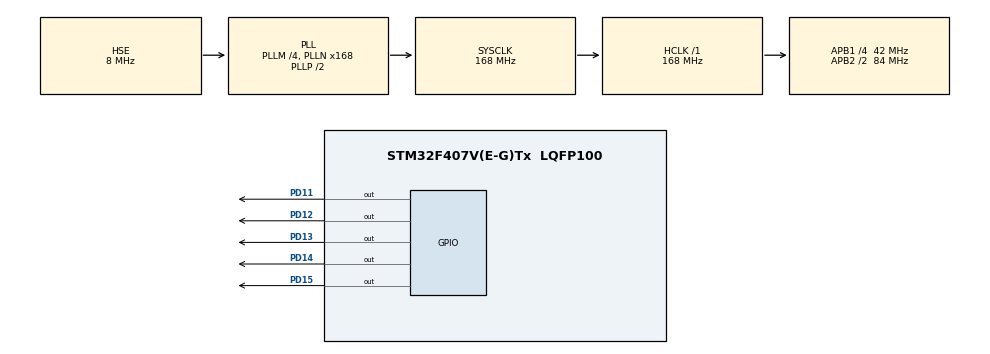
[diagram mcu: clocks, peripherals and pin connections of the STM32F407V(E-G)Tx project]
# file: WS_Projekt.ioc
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Dma.Request0=TIM1_CH4/TRIG/COM
Dma.Request1=TIM1_UP
Dma.Request2=TIM2_UP/CH3
Dma.TIM1_CH4/TRIG/COM.0.Direction=DMA_PERIPH_TO_MEMORY
Dma.TIM1_CH4/TRIG/COM.0.FIFOMode=DMA_FIFOMODE_DISABLE
Dma.TIM1_CH4/TRIG/COM.0.Instance=DMA2_Stream4
Dma.TIM1_CH4/TRIG/COM.0.MemDataAlignment=DMA_MDATAALIGN_HALFWORD
Dma.TIM1_CH4/TRIG/COM.0.MemInc=DMA_MINC_ENABLE
Dma.TIM1_CH4/TRIG/COM.0.Mode=DMA_NORMAL
Dma.TIM1_CH4/TRIG/COM.0.PeriphDataAlignment=DMA_PDATAALIGN_HALFWORD
Dma.TIM1_CH4/TRIG/COM.0.PeriphInc=DMA_PINC_DISABLE
Dma.TIM1_CH4/TRIG/COM.0.Priority=DMA_PRIORITY_LOW
Dma.TIM1_UP.1.Direction=DMA_PERIPH_TO_MEMORY
Dma.TIM1_UP.1.FIFOMode=DMA_FIFOMODE_DISABLE
Dma.TIM1_UP.1.Instance=DMA2_Stream5
Dma.TIM1_UP.1.MemDataAlignment=DMA_MDATAALIGN_BYTE
Dma.TIM1_UP.1.MemInc=DMA_MINC_ENABLE
Dma.TIM1_UP.1.Mode=DMA_NORMAL
Dma.TIM1_UP.1.PeriphDataAlignment=DMA_PDATAALIGN_BYTE
Dma.TIM1_UP.1.PeriphInc=DMA_PINC_DISABLE
Dma.TIM1_UP.1.Priority=DMA_PRIORITY_LOW
Dma.TIM2_UP/CH3.2.Direction=DMA_PERIPH_TO_MEMORY
Dma.TIM2_UP/CH3.2.FIFOMode=DMA_FIFOMODE_DISABLE
Dma.TIM2_UP/CH3.2.Instance=DMA1_Stream1
Dma.TIM2_UP/CH3.2.MemDataAlignment=DMA_MDATAALIGN_WORD
Dma.TIM2_UP/CH3.2.MemInc=DMA_MINC_ENABLE
Dma.TIM2_UP/CH3.2.Mode=DMA_NORMAL
Dma.TIM2_UP/CH3.2.PeriphDataAlignment=DMA_PDATAALIGN_WORD
Dma.TIM2_UP/CH3.2.PeriphInc=DMA_PINC_DISABLE
Dma.TIM2_UP/CH3.2.Priority=DMA_PRIORITY_LOW
Mcu.Family=STM32F4
Mcu.Name=STM32F407V(E-G)Tx
Mcu.Package=LQFP100
NVIC.DMA1_Stream1_IRQn=true\:0\:0\:false\:true\:true\:5\:false
NVIC.DMA2_Stream4_IRQn=true\:0\:0\:false\:true\:true\:6\:false
NVIC.DMA2_Stream5_IRQn=true\:0\:0\:false\:false\:true\:false
NVIC.PriorityGroup=NVIC_PRIORITYGROUP_4
NVIC.TIM1_CC_IRQn=true\:0\:0\:false\:true\:true\:2\:true
NVIC.TIM1_TRG_COM_TIM11_IRQn=true\:0\:0\:false\:true\:true\:3\:true
NVIC.TIM1_UP_TIM10_IRQn=true\:0\:0\:false\:true\:true\:4\:true
NVIC.TIM2_IRQn=true\:0\:0\:false\:true\:true\:1\:true
PD11.GPIO_Speed=GPIO_SPEED_FREQ_LOW
PD11.Signal=GPIO_Output
PD12.Signal=GPIO_Output
PD13.Signal=GPIO_Output
PD14.Signal=GPIO_Output
PD15.Signal=GPIO_Output
PH0-OSC_IN.Mode=HSE-External-Oscillator
PH0-OSC_IN.Signal=RCC_OSC_IN
PH1-OSC_OUT.Mode=HSE-External-Oscillator
PH1-OSC_OUT.Signal=RCC_OSC_OUT
ProjectManager.HeapSize=0x200
ProjectManager.StackSize=0x400
ProjectManager.TargetToolchain=SW4STM32
RCC.48MHZClocksFreq_Value=84000000
RCC.AHBFreq_Value=168000000
RCC.APB1CLKDivider=RCC_HCLK_DIV4
RCC.APB1Freq_Value=42000000
RCC.APB1TimFreq_Value=84000000
RCC.APB2CLKDivider=RCC_HCLK_DIV2
RCC.APB2Freq_Value=84000000
RCC.APB2TimFreq_Value=168000000
RCC.CortexFreq_Value=168000000
RCC.HCLKFreq_Value=168000000
RCC.HSE_VALUE=8000000
RCC.HSI_VALUE=16000000
RCC.LSE_VALUE=32768
RCC.PLLM=4
RCC.PLLN=168
RCC.PLLSourceVirtual=RCC_PLLSOURCE_HSE
RCC.SYSCLKFreq_VALUE=168000000
RCC.SYSCLKSource=RCC_SYSCLKSOURCE_PLLCLK
RCC.VCOOutputFreq_Value=336000000
TIM1.Period=2
TIM1.Prescaler=10
TIM2.Period=6719
TIM2.Prescaler=124
VP_TIM1_VS_ClockSourceINT.Mode=Internal
VP_TIM2_VS_ClockSourceINT.Mode=Internal
board=custom

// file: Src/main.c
/**
  ******************************************************************************
  * @file           : main.c
  * @brief          : Main program body
  ******************************************************************************
  ** This notice applies to any and all portions of this file
  * that are not between comment pairs USER CODE BEGIN and
  * USER CODE END. Other portions of this file, whether
  * inserted by the user or by software development tools
  * are owned by their respective copyright owners.
  *
  * COPYRIGHT(c) 2019 STMicroelectronics
  *
  * Redistribution and use in source and binary forms, with or without modification,
  * are permitted provided that the following conditions are met:
  *   1. Redistributions of source code must retain the above copyright notice,
  *      this list of conditions and the following disclaimer.
  *   2. Redistributions in binary form must reproduce the above copyright notice,
  *      this list of conditions and the following disclaimer in the documentation
  *      and/or other materials provided with the distribution.
  *   3. Neither the name of STMicroelectronics nor the names of its contributors
  *      may be used to endorse or promote products derived from this software
  *      without specific prior written permission.
  *
  * THIS SOFTWARE IS PROVIDED BY THE COPYRIGHT HOLDERS AND CONTRIBUTORS "AS IS"
  * AND ANY EXPRESS OR IMPLIED WARRANTIES, INCLUDING, BUT NOT LIMITED TO, THE
  * IMPLIED WARRANTIES OF MERCHANTABILITY AND FITNESS FOR A PARTICULAR PURPOSE ARE
  * DISCLAIMED. IN NO EVENT SHALL THE COPYRIGHT HOLDER OR CONTRIBUTORS BE LIABLE
  * FOR ANY DIRECT, INDIRECT, INCIDENTAL, SPECIAL, EXEMPLARY, OR CONSEQUENTIAL
  * DAMAGES (INCLUDING, BUT NOT LIMITED TO, PROCUREMENT OF SUBSTITUTE GOODS OR
  * SERVICES; LOSS OF USE, DATA, OR PROFITS; OR BUSINESS INTERRUPTION) HOWEVER
  * CAUSED AND ON ANY THEORY OF LIABILITY, WHETHER IN CONTRACT, STRICT LIABILITY,
  * OR TORT (INCLUDING NEGLIGENCE OR OTHERWISE) ARISING IN ANY WAY OUT OF THE USE
  * OF THIS SOFTWARE, EVEN IF ADVISED OF THE POSSIBILITY OF SUCH DAMAGE.
  *
  ******************************************************************************
  */
#include "main.h"
#include "stm32f4xx_hal.h"
#include "ws2812b.h"
#include "ws2812b_conf.h"

TIM_HandleTypeDef htim1;
TIM_HandleTypeDef htim2;
DMA_HandleTypeDef hdma_tim1_ch4_trig_com;
DMA_HandleTypeDef hdma_tim1_up;
DMA_HandleTypeDef hdma_tim2_up_ch3;

/* USER CODE BEGIN PV */
/* Private variables ---------------------------------------------------------*/

/* USER CODE END PV */

void SystemClock_Config(void);
static void MX_GPIO_Init(void);
static void MX_DMA_Init(void);
static void MX_TIM1_Init(void);
static void MX_TIM2_Init(void);
static void MX_NVIC_Init(void);

/* USER CODE BEGIN PFP */
/* Private function prototypes -----------------------------------------------*/

/* USER CODE END PFP */

/* USER CODE BEGIN 0 */
volatile int i = 0;
volatile int z = 0;
int numero = 0;
volatile int pin =0;
volatile int tab [] = {0,0,1,1,1,0,0,1,0,0,1,1,1,0,0,1,1,0,1,0,1,0,1,0};

/* USER CODE END 0 */
int main(void)
{
  /* USER CODE BEGIN 1 */
	//WS2812B_Init();

	//WS2812B_SetRGB(0, 0, 255, 40, 93);
	//WS2812B_SetRGB(0, 1, 0, 255, 0);
	//WS2812B_SetRGB(0, 2, 0, 0, 255);
  /* USER CODE END 1 */

  /* MCU Configuration----------------------------------------------------------*/

  /* Reset of all peripherals, Initializes the Flash interface and the Systick. */
  HAL_Init();

  /* Configure the system clock */
  SystemClock_Config();

  /* Initialize all configured peripherals */
  MX_GPIO_Init();
  MX_DMA_Init();
  MX_TIM1_Init();
  MX_TIM2_Init();

  /* Initialize interrupts */
  MX_NVIC_Init();
/*
  #define zero 0b11000000
  #define one 0b11111000
*/
  /* Infinite loop */
  /* USER CODE BEGIN WHILE */
  while (1)
  {
	  //HAL_GPIO_TogglePin(GPIOD, GPIO_PIN_12 | GPIO_PIN_13 | GPIO_PIN_14 | GPIO_PIN_15);
	  /*
	  if(numero < 240 && numero >= 0)
	  {*/
		  if(tab[z] == 1)
		  {
			  /*
			  for(int j=0;j<5;j++)
			  {
				  HAL_GPIO_WritePin(GPIOD,GPIO_PIN_12,1);
				  pin = 1;
			  }
			  for(int j=0;j<3;j++)
			  {
				  HAL_GPIO_WritePin(GPIOD,GPIO_PIN_12,0);
				  pin = 0;
			  }
			  */
			  HAL_GPIO_WritePin(GPIOD,GPIO_PIN_12,1);
			  pin = 1;
		  }
		  else if(tab[z] == 0)
		  {
			  /*
			  for(int j=0;j<2;j++)
			  {
				  HAL_GPIO_WritePin(GPIOD,GPIO_PIN_12,1);
				  pin = 1;
			  }
			  for(int j=0;j<6;j++)
			  {
				  HAL_GPIO_WritePin(GPIOD,GPIO_PIN_12,0);
				  pin = 0;
			  }
			  */
			  HAL_GPIO_WritePin(GPIOD,GPIO_PIN_12,0);
			  pin = 0;

			  //HAL_GPIO_WritePin(GPIO_PIN_12,0);
		  }
		  if(z < 23){z++;}
		  else if (z==23){z=0;}
		  for(int c=0;c<10000000;c++){}
		  //numero += 1;
	  /*}
	  else if(numero > 0)
	  {
		  numero = -2;
	  }

	  if(numero == -2)
	  {
		  HAL_GPIO_WritePin(GPIOD,GPIO_PIN_12,0);
		  numero--;
	  }

*/
  /* USER CODE END WHILE */

  }

}

void SystemClock_Config(void)
{

  RCC_OscInitTypeDef RCC_OscInitStruct;
  RCC_ClkInitTypeDef RCC_ClkInitStruct;

    /**Configure the main internal regulator output voltage
    */
  __HAL_RCC_PWR_CLK_ENABLE();

  __HAL_PWR_VOLTAGESCALING_CONFIG(PWR_REGULATOR_VOLTAGE_SCALE1);

    /**Initializes the CPU, AHB and APB busses clocks
    */
  RCC_OscInitStruct.OscillatorType = RCC_OSCILLATORTYPE_HSE;
  RCC_OscInitStruct.HSEState = RCC_HSE_ON;
  RCC_OscInitStruct.PLL.PLLState = RCC_PLL_ON;
  RCC_OscInitStruct.PLL.PLLSource = RCC_PLLSOURCE_HSE;
  RCC_OscInitStruct.PLL.PLLM = 4;
  RCC_OscInitStruct.PLL.PLLN = 168;
  RCC_OscInitStruct.PLL.PLLP = RCC_PLLP_DIV2;
  RCC_OscInitStruct.PLL.PLLQ = 4;
  if (HAL_RCC_OscConfig(&RCC_OscInitStruct) != HAL_OK)
  {
    _Error_Handler(__FILE__, __LINE__);
  }

    /**Initializes the CPU, AHB and APB busses clocks
    */
  RCC_ClkInitStruct.ClockType = RCC_CLOCKTYPE_HCLK|RCC_CLOCKTYPE_SYSCLK
                              |RCC_CLOCKTYPE_PCLK1|RCC_CLOCKTYPE_PCLK2;
  RCC_ClkInitStruct.SYSCLKSource = RCC_SYSCLKSOURCE_PLLCLK;
  RCC_ClkInitStruct.AHBCLKDivider = RCC_SYSCLK_DIV1;
  RCC_ClkInitStruct.APB1CLKDivider = RCC_HCLK_DIV4;
  RCC_ClkInitStruct.APB2CLKDivider = RCC_HCLK_DIV2;

  if (HAL_RCC_ClockConfig(&RCC_ClkInitStruct, FLASH_LATENCY_5) != HAL_OK)
  {
    _Error_Handler(__FILE__, __LINE__);
  }

    /**Configure the Systick interrupt time
    */
  HAL_SYSTICK_Config(HAL_RCC_GetHCLKFreq()/1000);

    /**Configure the Systick
    */
  HAL_SYSTICK_CLKSourceConfig(SYSTICK_CLKSOURCE_HCLK);

  /* SysTick_IRQn interrupt configuration */
  HAL_NVIC_SetPriority(SysTick_IRQn, 0, 0);
}

/**
  * @brief NVIC Configuration.
  * @retval None
  */
static void MX_NVIC_Init(void)
{
  /* TIM2_IRQn interrupt configuration */
  HAL_NVIC_SetPriority(TIM2_IRQn, 0, 0);
  HAL_NVIC_EnableIRQ(TIM2_IRQn);
  /* TIM1_CC_IRQn interrupt configuration */
  HAL_NVIC_SetPriority(TIM1_CC_IRQn, 0, 0);
  HAL_NVIC_EnableIRQ(TIM1_CC_IRQn);
  /* TIM1_TRG_COM_TIM11_IRQn interrupt configuration */
  HAL_NVIC_SetPriority(TIM1_TRG_COM_TIM11_IRQn, 0, 0);
  HAL_NVIC_EnableIRQ(TIM1_TRG_COM_TIM11_IRQn);
  /* TIM1_UP_TIM10_IRQn interrupt configuration */
  HAL_NVIC_SetPriority(TIM1_UP_TIM10_IRQn, 0, 0);
  HAL_NVIC_EnableIRQ(TIM1_UP_TIM10_IRQn);
  /* DMA1_Stream1_IRQn interrupt configuration */
  HAL_NVIC_SetPriority(DMA1_Stream1_IRQn, 0, 0);
  HAL_NVIC_EnableIRQ(DMA1_Stream1_IRQn);
  /* DMA2_Stream4_IRQn interrupt configuration */
  HAL_NVIC_SetPriority(DMA2_Stream4_IRQn, 0, 0);
  HAL_NVIC_EnableIRQ(DMA2_Stream4_IRQn);
}

/* TIM1 init function */
static void MX_TIM1_Init(void)
{

  TIM_ClockConfigTypeDef sClockSourceConfig;
  TIM_MasterConfigTypeDef sMasterConfig;

  htim1.Instance = TIM1;
  htim1.Init.Prescaler = 10;
  htim1.Init.CounterMode = TIM_COUNTERMODE_UP;
  htim1.Init.Period = 2;
  htim1.Init.ClockDivision = TIM_CLOCKDIVISION_DIV1;
  htim1.Init.RepetitionCounter = 0;
  if (HAL_TIM_Base_Init(&htim1) != HAL_OK)
  {
    _Error_Handler(__FILE__, __LINE__);
  }

  sClockSourceConfig.ClockSource = TIM_CLOCKSOURCE_INTERNAL;
  if (HAL_TIM_ConfigClockSource(&htim1, &sClockSourceConfig) != HAL_OK)
  {
    _Error_Handler(__FILE__, __LINE__);
  }

  sMasterConfig.MasterOutputTrigger = TIM_TRGO_RESET;
  sMasterConfig.MasterSlaveMode = TIM_MASTERSLAVEMODE_DISABLE;
  if (HAL_TIMEx_MasterConfigSynchronization(&htim1, &sMasterConfig) != HAL_OK)
  {
    _Error_Handler(__FILE__, __LINE__);
  }

}

/* TIM2 init function */
static void MX_TIM2_Init(void)
{

  TIM_ClockConfigTypeDef sClockSourceConfig;
  TIM_MasterConfigTypeDef sMasterConfig;

  htim2.Instance = TIM2;
  htim2.Init.Prescaler = 124;
  htim2.Init.CounterMode = TIM_COUNTERMODE_UP;
  htim2.Init.Period = 6719;
  htim2.Init.ClockDivision = TIM_CLOCKDIVISION_DIV1;
  if (HAL_TIM_Base_Init(&htim2) != HAL_OK)
  {
    _Error_Handler(__FILE__, __LINE__);
  }

  sClockSourceConfig.ClockSource = TIM_CLOCKSOURCE_INTERNAL;
  if (HAL_TIM_ConfigClockSource(&htim2, &sClockSourceConfig) != HAL_OK)
  {
    _Error_Handler(__FILE__, __LINE__);
  }

  sMasterConfig.MasterOutputTrigger = TIM_TRGO_RESET;
  sMasterConfig.MasterSlaveMode = TIM_MASTERSLAVEMODE_DISABLE;
  if (HAL_TIMEx_MasterConfigSynchronization(&htim2, &sMasterConfig) != HAL_OK)
  {
    _Error_Handler(__FILE__, __LINE__);
  }

}

static void MX_DMA_Init(void)
{
  /* DMA controller clock enable */
  __HAL_RCC_DMA2_CLK_ENABLE();
  __HAL_RCC_DMA1_CLK_ENABLE();

  /* DMA interrupt init */
  /* DMA2_Stream5_IRQn interrupt configuration */
  HAL_NVIC_SetPriority(DMA2_Stream5_IRQn, 0, 0);
  HAL_NVIC_EnableIRQ(DMA2_Stream5_IRQn);

}

/** Configure pins as
        * Analog
        * Input
        * Output
        * EVENT_OUT
        * EXTI
*/
static void MX_GPIO_Init(void)
{

  GPIO_InitTypeDef GPIO_InitStruct;

  /* GPIO Ports Clock Enable */
  __HAL_RCC_GPIOH_CLK_ENABLE();
  __HAL_RCC_GPIOD_CLK_ENABLE();

  /*Configure GPIO pin Output Level */
  HAL_GPIO_WritePin(GPIOD, GPIO_PIN_11|GPIO_PIN_12|GPIO_PIN_13|GPIO_PIN_14
                          |GPIO_PIN_15, GPIO_PIN_RESET);

  /*Configure GPIO pins : PD11 PD12 PD13 PD14
                           PD15 */
  GPIO_InitStruct.Pin = GPIO_PIN_11|GPIO_PIN_12|GPIO_PIN_13|GPIO_PIN_14 |GPIO_PIN_15;
  GPIO_InitStruct.Mode = GPIO_MODE_OUTPUT_PP;
  GPIO_InitStruct.Pull = GPIO_NOPULL;
  GPIO_InitStruct.Speed = GPIO_SPEED_FREQ_LOW;
  HAL_GPIO_Init(GPIOD, &GPIO_InitStruct);

}

void _Error_Handler(char *file, int line)
{
  while(1)
  {
  }
}

/************************ (C) COPYRIGHT STMicroelectronics *****END OF FILE****/
